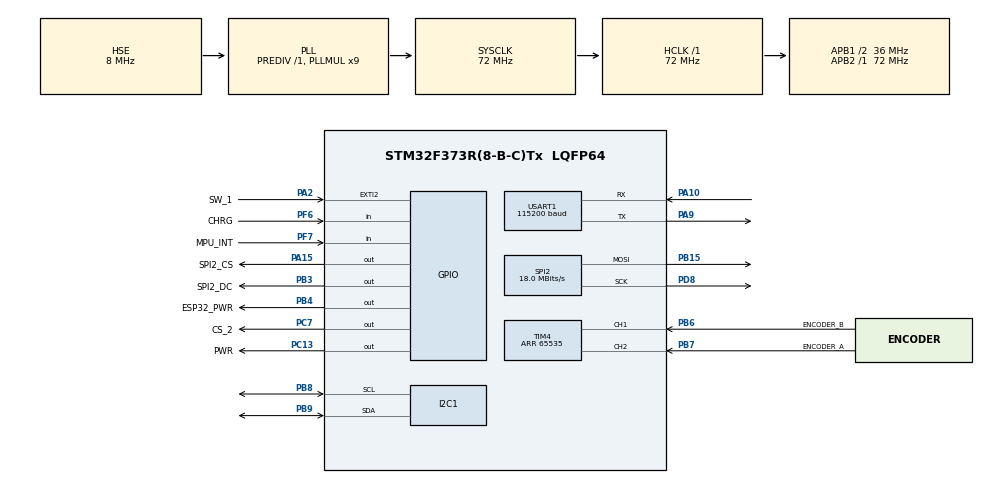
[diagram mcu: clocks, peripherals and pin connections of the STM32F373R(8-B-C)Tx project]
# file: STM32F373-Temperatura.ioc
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Mcu.Family=STM32F3
Mcu.Name=STM32F373R(8-B-C)Tx
Mcu.Package=LQFP64
NVIC.EXTI2_TSC_IRQn=true\:0\:0\:false\:false\:true\:true\:true
NVIC.PriorityGroup=NVIC_PRIORITYGROUP_4
NVIC.USART1_IRQn=true\:0\:0\:false\:false\:true\:true\:true
PA10.Mode=Asynchronous
PA10.Signal=USART1_RX
PA13.Mode=Serial_Wire
PA13.Signal=SYS_JTMS-SWDIO
PA14.Mode=Serial_Wire
PA14.Signal=SYS_JTCK-SWCLK
PA15.GPIO_Label=SPI2_CS
PA15.GPIO_Speed=GPIO_SPEED_FREQ_HIGH
PA15.Signal=GPIO_Output
PA2.GPIO_Label=SW_1
PA2.GPIO_ModeDefaultEXTI=GPIO_MODE_IT_RISING
PA2.GPIO_PuPd=GPIO_PULLDOWN
PA2.Signal=GPXTI2
PA9.Mode=Asynchronous
PA9.Signal=USART1_TX
PB15.Mode=TX_Only_Simplex_Unidirect_Master
PB15.Signal=SPI2_MOSI
PB3.GPIO_Label=SPI2_DC
PB3.GPIO_ModeDefaultOutputPP=GPIO_MODE_OUTPUT_PP
PB3.GPIO_Speed=GPIO_SPEED_FREQ_HIGH
PB3.Signal=GPIO_Output
PB4.GPIO_Label=ESP32_PWR
PB4.GPIO_ModeDefaultOutputPP=GPIO_MODE_OUTPUT_PP
PB4.GPIO_PuPd=GPIO_NOPULL
PB4.PinState=GPIO_PIN_RESET
PB4.Signal=GPIO_Output
PB5.GPIO_Label=BUZZER
PB5.Signal=S_TIM17_CH1
PB6.GPIO_Label=ENCODER_B
PB6.GPIO_ModeDefaultPP=GPIO_MODE_AF_OD
PB6.GPIO_PuPd=GPIO_PULLUP
PB6.Signal=S_TIM4_CH1
PB7.GPIO_Label=ENCODER_A
PB7.GPIO_ModeDefaultPP=GPIO_MODE_AF_OD
PB7.GPIO_PuPd=GPIO_PULLUP
PB7.Signal=S_TIM4_CH2
PB8.Mode=I2C
PB8.Signal=I2C1_SCL
PB9.Mode=I2C
PB9.Signal=I2C1_SDA
PC13.GPIO_Label=PWR
PC13.PinState=GPIO_PIN_SET
PC13.Signal=GPIO_Output
PC14-OSC32_IN.Mode=LSE-External-Oscillator
PC14-OSC32_IN.Signal=RCC_OSC32_IN
PC15-OSC32_OUT.Mode=LSE-External-Oscillator
PC15-OSC32_OUT.Signal=RCC_OSC32_OUT
PC7.GPIO_Label=CS_2
PC7.Signal=GPIO_Output
PD8.Mode=TX_Only_Simplex_Unidirect_Master
PD8.Signal=SPI2_SCK
PF0-OSC_IN.Mode=HSE-External-Oscillator
PF0-OSC_IN.Signal=RCC_OSC_IN
PF1-OSC_OUT.Mode=HSE-External-Oscillator
PF1-OSC_OUT.Signal=RCC_OSC_OUT
PF6.GPIO_Label=CHRG
PF6.GPIO_PuPd=GPIO_PULLUP
PF6.Signal=GPIO_Input
PF7.GPIO_Label=MPU_INT
PF7.Signal=GPIO_Input
ProjectManager.HeapSize=0x200
ProjectManager.StackSize=0x400
ProjectManager.TargetToolchain=Other Toolchains (GPDSC)
RCC.AHBFreq_Value=72000000
RCC.APB1CLKDivider=RCC_HCLK_DIV2
RCC.APB1Freq_Value=36000000
RCC.APB1TimFreq_Value=72000000
RCC.APB2Freq_Value=72000000
RCC.APB2TimFreq_Value=72000000
RCC.CortexFreq_Value=72000000
RCC.HCLKFreq_Value=72000000
RCC.HSE_VALUE=8000000
RCC.HSI_VALUE=8000000
RCC.PLLMUL=RCC_PLL_MUL9
RCC.PLLSourceVirtual=RCC_PLLSOURCE_HSE
RCC.PRESCALERUSB=RCC_USBCLKSOURCE_PLL_DIV1_5
RCC.RTCClockSelection=RCC_RTCCLKSOURCE_LSE
RCC.SDADCPresc=RCC_SDADCSYSCLK_DIV24
RCC.SYSCLKFreq_VALUE=72000000
RCC.SYSCLKSource=RCC_SYSCLKSOURCE_PLLCLK
RCC.USBFreq_Value=48000000
SH.S_TIM17_CH1.0=TIM17_CH1
SH.S_TIM4_CH1.0=TIM4_CH1,Encoder_Interface
SH.S_TIM4_CH2.0=TIM4_CH2,Encoder_Interface
SPI2.CalculateBaudRate=18.0 MBits/s
SPI2.DataSize=SPI_DATASIZE_8BIT
SPI2.Direction=SPI_DIRECTION_2LINES
SPI2.Mode=SPI_MODE_MASTER
SPI2.NSSPMode=SPI_NSS_PULSE_ENABLE
SPI2.VirtualType=VM_MASTER
TIM17.AutoReloadPreload=TIM_AUTORELOAD_PRELOAD_ENABLE
TIM17.Period=100
TIM17.Prescaler=300
TIM4.Period=65535
USART1.BaudRate=115200
USART1.VirtualMode-Asynchronous=VM_ASYNC
VP_RTC_VS_RTC_Activate.Mode=RTC_Enabled
VP_TIM17_VS_ClockSourceINT.Mode=Enable_Timer
VP_WWDG_VS_WWDG.Mode=WWDG_Activate
WWDG.Counter=127
WWDG.Prescaler=WWDG_PRESCALER_8
WWDG.Window=127
board=custom

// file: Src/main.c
/**
  ******************************************************************************
  * @file           : main.c
  * @brief          : Main program body
  ******************************************************************************
  ** This notice applies to any and all portions of this file
  * that are not between comment pairs USER CODE BEGIN and
  * USER CODE END. Other portions of this file, whether
  * inserted by the user or by software development tools
  * are owned by their respective copyright owners.
  *
  * COPYRIGHT(c) 2021 STMicroelectronics
  *
  * Redistribution and use in source and binary forms, with or without modification,
  * are permitted provided that the following conditions are met:
  *   1. Redistributions of source code must retain the above copyright notice,
  *      this list of conditions and the following disclaimer.
  *   2. Redistributions in binary form must reproduce the above copyright notice,
  *      this list of conditions and the following disclaimer in the documentation
  *      and/or other materials provided with the distribution.
  *   3. Neither the name of STMicroelectronics nor the names of its contributors
  *      may be used to endorse or promote products derived from this software
  *      without specific prior written permission.
  *
  * THIS SOFTWARE IS PROVIDED BY THE COPYRIGHT HOLDERS AND CONTRIBUTORS "AS IS"
  * AND ANY EXPRESS OR IMPLIED WARRANTIES, INCLUDING, BUT NOT LIMITED TO, THE
  * IMPLIED WARRANTIES OF MERCHANTABILITY AND FITNESS FOR A PARTICULAR PURPOSE ARE
  * DISCLAIMED. IN NO EVENT SHALL THE COPYRIGHT HOLDER OR CONTRIBUTORS BE LIABLE
  * FOR ANY DIRECT, INDIRECT, INCIDENTAL, SPECIAL, EXEMPLARY, OR CONSEQUENTIAL
  * DAMAGES (INCLUDING, BUT NOT LIMITED TO, PROCUREMENT OF SUBSTITUTE GOODS OR
  * SERVICES; LOSS OF USE, DATA, OR PROFITS; OR BUSINESS INTERRUPTION) HOWEVER
  * CAUSED AND ON ANY THEORY OF LIABILITY, WHETHER IN CONTRACT, STRICT LIABILITY,
  * OR TORT (INCLUDING NEGLIGENCE OR OTHERWISE) ARISING IN ANY WAY OUT OF THE USE
  * OF THIS SOFTWARE, EVEN IF ADVISED OF THE POSSIBILITY OF SUCH DAMAGE.
  *
  ******************************************************************************
  */
#include "main.h"
#include "stm32f3xx_hal.h"
#include "i2c.h"
#include "rtc.h"
#include "spi.h"
#include "tim.h"
#include "usart.h"
#include "wwdg.h"
#include "gpio.h"

/* USER CODE BEGIN Includes */
#include "OLED_Hal_SPI.h"
#include "temperatura.hpp"
#include "interface_comunicacao.hpp"
#include "Encoder.h"
/* USER CODE END Includes */

/* USER CODE BEGIN PV */
/* Private variables ---------------------------------------------------------*/

/* USER CODE END PV */

void SystemClock_Config(void);

/* USER CODE BEGIN PFP */
/* Private function prototypes -----------------------------------------------*/

/* USER CODE END PFP */

int main(void)
{

  /* MCU Configuration----------------------------------------------------------*/

  /* Reset of all peripherals, Initializes the Flash interface and the Systick. */
  HAL_Init();

  /* Configure the system clock */
  SystemClock_Config();

  /* Initialize all configured peripherals */
  MX_GPIO_Init();
  MX_USART1_UART_Init();
  MX_SPI2_Init();
  MX_WWDG_Init();
  MX_RTC_Init();
  MX_TIM4_Init();
  MX_TIM17_Init();
  MX_I2C1_Init();
  /* USER CODE BEGIN 2 */
  Oled_Init();
  Encoder_Init();
  acelerometro_ambiente_setup();
  /* USER CODE END 2 */

  /* Infinite loop */
  /* USER CODE BEGIN WHILE */
  while (1)
  {
    Encoder();
    if (tecla)
    {
      uart_print("tecla pressionada ");
    }
    uart_print("encoder pos : %d\r\n", encoder);
    /* USER CODE END WHILE */

    /* USER CODE BEGIN 3 */
    acelerometro_ambiente_loop();
    HAL_WWDG_Refresh(&hwwdg);
  }
  /* USER CODE END 3 */
}

void SystemClock_Config(void)
{

  RCC_OscInitTypeDef RCC_OscInitStruct;
  RCC_ClkInitTypeDef RCC_ClkInitStruct;
  RCC_PeriphCLKInitTypeDef PeriphClkInit;

  /**Configure LSE Drive Capability
    */
  HAL_PWR_EnableBkUpAccess();

  __HAL_RCC_LSEDRIVE_CONFIG(RCC_LSEDRIVE_LOW);

  /**Initializes the CPU, AHB and APB busses clocks
    */
  RCC_OscInitStruct.OscillatorType = RCC_OSCILLATORTYPE_HSI | RCC_OSCILLATORTYPE_HSE | RCC_OSCILLATORTYPE_LSE;
  RCC_OscInitStruct.HSEState = RCC_HSE_ON;
  RCC_OscInitStruct.HSEPredivValue = RCC_HSE_PREDIV_DIV1;
  RCC_OscInitStruct.LSEState = RCC_LSE_ON;
  RCC_OscInitStruct.HSIState = RCC_HSI_ON;
  RCC_OscInitStruct.HSICalibrationValue = 16;
  RCC_OscInitStruct.PLL.PLLState = RCC_PLL_ON;
  RCC_OscInitStruct.PLL.PLLSource = RCC_PLLSOURCE_HSE;
  RCC_OscInitStruct.PLL.PLLMUL = RCC_PLL_MUL9;
  if (HAL_RCC_OscConfig(&RCC_OscInitStruct) != HAL_OK)
  {
    _Error_Handler(__FILE__, __LINE__);
  }

  /**Initializes the CPU, AHB and APB busses clocks
    */
  RCC_ClkInitStruct.ClockType = RCC_CLOCKTYPE_HCLK | RCC_CLOCKTYPE_SYSCLK | RCC_CLOCKTYPE_PCLK1 | RCC_CLOCKTYPE_PCLK2;
  RCC_ClkInitStruct.SYSCLKSource = RCC_SYSCLKSOURCE_PLLCLK;
  RCC_ClkInitStruct.AHBCLKDivider = RCC_SYSCLK_DIV1;
  RCC_ClkInitStruct.APB1CLKDivider = RCC_HCLK_DIV2;
  RCC_ClkInitStruct.APB2CLKDivider = RCC_HCLK_DIV1;

  if (HAL_RCC_ClockConfig(&RCC_ClkInitStruct, FLASH_LATENCY_2) != HAL_OK)
  {
    _Error_Handler(__FILE__, __LINE__);
  }

  PeriphClkInit.PeriphClockSelection = RCC_PERIPHCLK_USART1 | RCC_PERIPHCLK_I2C1 | RCC_PERIPHCLK_RTC;
  PeriphClkInit.Usart1ClockSelection = RCC_USART1CLKSOURCE_PCLK2;
  PeriphClkInit.I2c1ClockSelection = RCC_I2C1CLKSOURCE_HSI;
  PeriphClkInit.RTCClockSelection = RCC_RTCCLKSOURCE_LSE;
  if (HAL_RCCEx_PeriphCLKConfig(&PeriphClkInit) != HAL_OK)
  {
    _Error_Handler(__FILE__, __LINE__);
  }

  /**Configure the Systick interrupt time
    */
  HAL_SYSTICK_Config(HAL_RCC_GetHCLKFreq() / 1000);

  /**Configure the Systick
    */
  HAL_SYSTICK_CLKSourceConfig(SYSTICK_CLKSOURCE_HCLK);

  /* SysTick_IRQn interrupt configuration */
  HAL_NVIC_SetPriority(SysTick_IRQn, 0, 0);
}

void _Error_Handler(char *file, int line)
{
  while (1)
  {
  }
}

/************************ (C) COPYRIGHT STMicroelectronics *****END OF FILE****/
